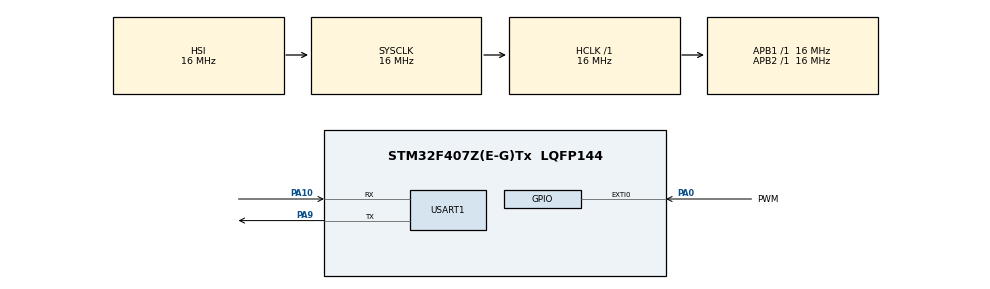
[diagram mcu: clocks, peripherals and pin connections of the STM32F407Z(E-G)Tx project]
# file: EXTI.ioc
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Mcu.Family=STM32F4
Mcu.Name=STM32F407Z(E-G)Tx
Mcu.Package=LQFP144
NVIC.EXTI0_IRQn=true\:0\:0\:false\:false\:true\:true\:true\:true
NVIC.PriorityGroup=NVIC_PRIORITYGROUP_4
PA0-WKUP.GPIO_Label=PWM
PA0-WKUP.GPIO_ModeDefaultEXTI=GPIO_MODE_IT_RISING
PA0-WKUP.GPIO_PuPd=GPIO_PULLDOWN
PA0-WKUP.Signal=GPXTI0
PA10.Mode=Asynchronous
PA10.Signal=USART1_RX
PA9.Mode=Asynchronous
PA9.Signal=USART1_TX
ProjectManager.HeapSize=0x200
ProjectManager.StackSize=0x400
ProjectManager.TargetToolchain=MDK-ARM V5.32
RCC.AHBFreq_Value=16000000
RCC.APB1Freq_Value=16000000
RCC.APB2Freq_Value=16000000
RCC.CortexFreq_Value=16000000
RCC.HSE_VALUE=25000000
RCC.HSI_VALUE=16000000
RCC.LSE_VALUE=32768
RCC.SYSCLKFreq_VALUE=16000000
RCC.VCOOutputFreq_Value=192000000
USART1.VirtualMode=VM_ASYNC
board=custom

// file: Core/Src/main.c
/* USER CODE BEGIN Header */
/**
  ******************************************************************************
  * @file           : main.c
  * @brief          : Main program body
  ******************************************************************************
  * @attention
  *
  * Copyright (c) 2024 STMicroelectronics.
  * All rights reserved.
  *
  * This software is licensed under terms that can be found in the LICENSE file
  * in the root directory of this software component.
  * If no LICENSE file comes with this software, it is provided AS-IS.
  *
  ******************************************************************************
  */
/* USER CODE END Header */
#include "main.h"
#include "usart.h"
#include "gpio.h"

/* USER CODE BEGIN Includes */
#include <stdio.h>
/* USER CODE END Includes */

/* USER CODE BEGIN PV */
int fputc(int ch,FILE *f)
{
    uint8_t temp[1]={ch};
    HAL_UART_Transmit(&huart1, temp, 1, 2);
	return ch;
}

int pwm_value = 0;
/* USER CODE END PV */

void SystemClock_Config(void);

int main(void)
{

  /* MCU Configuration--------------------------------------------------------*/

  /* Reset of all peripherals, Initializes the Flash interface and the Systick. */
  HAL_Init();

  /* Configure the system clock */
  SystemClock_Config();

  /* Initialize all configured peripherals */
  MX_GPIO_Init();
  MX_USART1_UART_Init();

  /* Infinite loop */
  /* USER CODE BEGIN WHILE */
  while (1)
  {

    pwm_value = 0; // pwm_value置0，这个是必须要做的，数据要刷新
    HAL_Delay(1000); // 延时1s
    printf("[\tmain]info:pwm_value=%d\r\n",pwm_value); // 读取pwm_value

    /* USER CODE END WHILE */

  }
}

void SystemClock_Config(void)
{
  RCC_OscInitTypeDef RCC_OscInitStruct = {0};
  RCC_ClkInitTypeDef RCC_ClkInitStruct = {0};

  /** Configure the main internal regulator output voltage
  */
  __HAL_RCC_PWR_CLK_ENABLE();
  __HAL_PWR_VOLTAGESCALING_CONFIG(PWR_REGULATOR_VOLTAGE_SCALE1);

  /** Initializes the RCC Oscillators according to the specified parameters
  * in the RCC_OscInitTypeDef structure.
  */
  RCC_OscInitStruct.OscillatorType = RCC_OSCILLATORTYPE_HSI;
  RCC_OscInitStruct.HSIState = RCC_HSI_ON;
  RCC_OscInitStruct.HSICalibrationValue = RCC_HSICALIBRATION_DEFAULT;
  RCC_OscInitStruct.PLL.PLLState = RCC_PLL_NONE;
  if (HAL_RCC_OscConfig(&RCC_OscInitStruct) != HAL_OK)
  {
    Error_Handler();
  }

  /** Initializes the CPU, AHB and APB buses clocks
  */
  RCC_ClkInitStruct.ClockType = RCC_CLOCKTYPE_HCLK|RCC_CLOCKTYPE_SYSCLK
                              |RCC_CLOCKTYPE_PCLK1|RCC_CLOCKTYPE_PCLK2;
  RCC_ClkInitStruct.SYSCLKSource = RCC_SYSCLKSOURCE_HSI;
  RCC_ClkInitStruct.AHBCLKDivider = RCC_SYSCLK_DIV1;
  RCC_ClkInitStruct.APB1CLKDivider = RCC_HCLK_DIV1;
  RCC_ClkInitStruct.APB2CLKDivider = RCC_HCLK_DIV1;

  if (HAL_RCC_ClockConfig(&RCC_ClkInitStruct, FLASH_LATENCY_0) != HAL_OK)
  {
    Error_Handler();
  }
}

/* USER CODE BEGIN 4 */
void HAL_GPIO_EXTI_Callback(uint16_t GPIO_Pin)
{
	if(GPIO_Pin == PWM_Pin)
	{ // 判断触发引脚是否是定义的引脚
	pwm_value++;
}

}

/* USER CODE END 4 */

void Error_Handler(void)
{
  __disable_irq();
  while (1)
  {
  }
}
